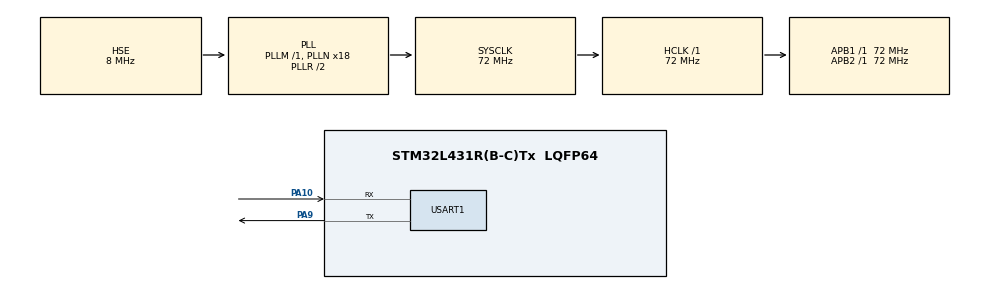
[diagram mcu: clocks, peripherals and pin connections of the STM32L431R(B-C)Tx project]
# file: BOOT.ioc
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Mcu.Family=STM32L4
Mcu.Name=STM32L431R(B-C)Tx
Mcu.Package=LQFP64
NVIC.PriorityGroup=NVIC_PRIORITYGROUP_4
NVIC.USART1_IRQn=true\:0\:0\:false\:false\:true\:true\:true
PA10.Mode=Asynchronous
PA10.Signal=USART1_RX
PA13\ (JTMS-SWDIO).Mode=Serial_Wire
PA13\ (JTMS-SWDIO).Signal=SYS_JTMS-SWDIO
PA14\ (JTCK-SWCLK).Mode=Serial_Wire
PA14\ (JTCK-SWCLK).Signal=SYS_JTCK-SWCLK
PA9.Mode=Asynchronous
PA9.Signal=USART1_TX
PC14-OSC32_IN\ (PC14).Mode=LSE-External-Oscillator
PC14-OSC32_IN\ (PC14).Signal=RCC_OSC32_IN
PC15-OSC32_OUT\ (PC15).Mode=LSE-External-Oscillator
PC15-OSC32_OUT\ (PC15).Signal=RCC_OSC32_OUT
PH0-OSC_IN\ (PH0).Mode=HSE-External-Oscillator
PH0-OSC_IN\ (PH0).Signal=RCC_OSC_IN
PH1-OSC_OUT\ (PH1).Mode=HSE-External-Oscillator
PH1-OSC_OUT\ (PH1).Signal=RCC_OSC_OUT
ProjectManager.HeapSize=0x200
ProjectManager.StackSize=0x400
ProjectManager.TargetToolchain=MDK-ARM V5.27
RCC.ADCFreq_Value=32000000
RCC.AHBFreq_Value=72000000
RCC.APB1Freq_Value=72000000
RCC.APB1TimFreq_Value=72000000
RCC.APB2Freq_Value=72000000
RCC.APB2TimFreq_Value=72000000
RCC.CortexFreq_Value=72000000
RCC.HCLKFreq_Value=72000000
RCC.HSE_VALUE=8000000
RCC.HSI48_VALUE=48000000
RCC.HSI_VALUE=16000000
RCC.MSI_VALUE=4000000
RCC.PLLN=18
RCC.PLLSourceVirtual=RCC_PLLSOURCE_HSE
RCC.SYSCLKFreq_VALUE=72000000
RCC.SYSCLKSource=RCC_SYSCLKSOURCE_PLLCLK
RCC.VCOOutputFreq_Value=144000000
USART1.VirtualMode-Asynchronous=VM_ASYNC
board=custom

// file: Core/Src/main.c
/* USER CODE BEGIN Header */
/**
  ******************************************************************************
  * @file           : main.c
  * @brief          : Main program body
  ******************************************************************************
  * @attention
  *
  * <h2><center>&copy; Copyright (c) 2020 STMicroelectronics.
  * All rights reserved.</center></h2>
  *
  * This software component is licensed by ST under BSD 3-Clause license,
  * the "License"; You may not use this file except in compliance with the
  * License. You may obtain a copy of the License at:
  *                        opensource.org/licenses/BSD-3-Clause
  *
  ******************************************************************************
  */
/* USER CODE END Header */
#include "main.h"
#include "usart.h"
#include "gpio.h"

void SystemClock_Config(void);

int main(void)
{

  /* MCU Configuration--------------------------------------------------------*/

  /* Reset of all peripherals, Initializes the Flash interface and the Systick. */
  HAL_Init();

  /* Configure the system clock */
  SystemClock_Config();

  /* Initialize all configured peripherals */
  MX_GPIO_Init();
  MX_USART1_UART_Init();

  /* Infinite loop */
  while (1)
  {

    /* USER CODE BEGIN 3 */
		Start_BootLoader();
		printf("sys is running!\r\n");
		HAL_Delay(5000);

  }
  /* USER CODE END 3 */
}

void SystemClock_Config(void)
{
  RCC_OscInitTypeDef RCC_OscInitStruct = {0};
  RCC_ClkInitTypeDef RCC_ClkInitStruct = {0};
  RCC_PeriphCLKInitTypeDef PeriphClkInit = {0};

  /** Initializes the RCC Oscillators according to the specified parameters
  * in the RCC_OscInitTypeDef structure.
  */
  RCC_OscInitStruct.OscillatorType = RCC_OSCILLATORTYPE_HSE;
  RCC_OscInitStruct.HSEState = RCC_HSE_ON;
  RCC_OscInitStruct.PLL.PLLState = RCC_PLL_ON;
  RCC_OscInitStruct.PLL.PLLSource = RCC_PLLSOURCE_HSE;
  RCC_OscInitStruct.PLL.PLLM = 1;
  RCC_OscInitStruct.PLL.PLLN = 18;
  RCC_OscInitStruct.PLL.PLLP = RCC_PLLP_DIV7;
  RCC_OscInitStruct.PLL.PLLQ = RCC_PLLQ_DIV2;
  RCC_OscInitStruct.PLL.PLLR = RCC_PLLR_DIV2;
  if (HAL_RCC_OscConfig(&RCC_OscInitStruct) != HAL_OK)
  {
    Error_Handler();
  }
  /** Initializes the CPU, AHB and APB buses clocks
  */
  RCC_ClkInitStruct.ClockType = RCC_CLOCKTYPE_HCLK|RCC_CLOCKTYPE_SYSCLK
                              |RCC_CLOCKTYPE_PCLK1|RCC_CLOCKTYPE_PCLK2;
  RCC_ClkInitStruct.SYSCLKSource = RCC_SYSCLKSOURCE_PLLCLK;
  RCC_ClkInitStruct.AHBCLKDivider = RCC_SYSCLK_DIV1;
  RCC_ClkInitStruct.APB1CLKDivider = RCC_HCLK_DIV1;
  RCC_ClkInitStruct.APB2CLKDivider = RCC_HCLK_DIV1;

  if (HAL_RCC_ClockConfig(&RCC_ClkInitStruct, FLASH_LATENCY_4) != HAL_OK)
  {
    Error_Handler();
  }
  PeriphClkInit.PeriphClockSelection = RCC_PERIPHCLK_USART1;
  PeriphClkInit.Usart1ClockSelection = RCC_USART1CLKSOURCE_PCLK2;
  if (HAL_RCCEx_PeriphCLKConfig(&PeriphClkInit) != HAL_OK)
  {
    Error_Handler();
  }
  /** Configure the main internal regulator output voltage
  */
  if (HAL_PWREx_ControlVoltageScaling(PWR_REGULATOR_VOLTAGE_SCALE1) != HAL_OK)
  {
    Error_Handler();
  }
}

void Error_Handler(void)
{
  __disable_irq();
  while (1)
  {
  }
}

/************************ (C) COPYRIGHT STMicroelectronics *****END OF FILE****/
